# YTM32B1MD2 register map
Vendor: YTMicro; File version: 1.0
CPU: CM33 r0p4, little endian, MPU, FPU, 2 interrupt priority bits
Registers are 32-bit, read-write, reset 0x0 unless marked. A register's access mark holds for its fields unless they carry their own. Offsets are from the block's base; [hi:lo] are bit positions; {n}, {i} and the like mark numbered series.

## TRNG0 — True Random Number Generator
Base 0x40066000; register names take the prefix TRNG0_
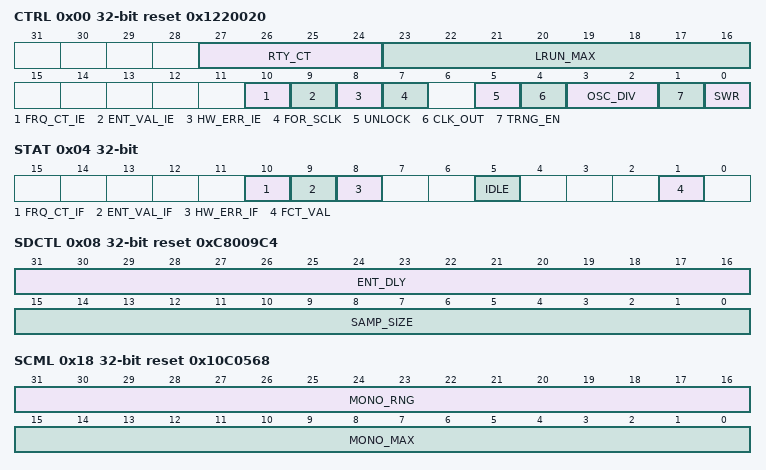
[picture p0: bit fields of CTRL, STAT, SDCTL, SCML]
0x00 CTRL reset 0x1220020
  [27:24] RTY_CT — It indicates the number of times a retry should occur before generating an error. Retry occurs when the statistical check fails during the TRNG entropy generation. This bit is writable only if UNLOCK bit is 1, or the UNLOCK bit is being written to 1 simultaneously.
  [23:16] LRUN_MAX — It is the largest allowable number of consecutive samples of all 1 or all 0 during the entropy generation. This bit is writable only if UNLOCK bit is 1, or the UNLOCK bit is being written to 1 simultaneously.
  [10] FRQ_CT_IE
    0=Interrupt disable; 1=Interrupt enable
  [9] ENT_VAL_IE
    0=Interrupt disable; 1=Interrupt enable
  [8] HW_ERR_IE
    0=Interrupt disable; 1=Interrupt enable
  [7] FOR_SCLK — If the bit is set, the system clock is used to operate the TRNG instead of the ring OSC. This bit is writable only if UNLOCK bit is 1, or the UNLOCK bit is being written to 1 simultaneously.
    0=No effect; 1=Force the system clock to operate the TRNG instead of the ring OSC
  [5] UNLOCK — This bit can prevent the value of various control bits from changing due to unexpected operation.
    0=Lock. Write to the control bits has no effect. Write 0 to start entropy generation.; 1=Unlock. The control bits are able to be modified. Write 1 to stop entropy generation.
  [4] CLK_OUT — After divided by 10, trng_osc_clk is output for test.
    0=No effect; 1=trng_osc_clk is output for test
  [3:2] OSC_DIV — This field is writable only if UNLOCK bit is 1, or the UNLOCK bit is being written to 1 simultaneously.
    0=No devider; 1=Ring OSC divided by 2; 2=Ring OSC divided by 4; 3=Ring OSC divided by 8
  [1] TRNG_EN — Enable the TRNG to generate and entropy value that can be read via ENT registers.
    0=TRNG disable; 1=TRNG enable
  [0] SWR wo — Writing 1 to this bit clears various TRNG registers(RTY_CT, LRUN_MAX, FOR_SCLK, CLK_OUT, OSC_DIV, SAMP_SIZE and SCML) to their default state. This bit is writable only if UNLOCK bit is 1, or the UNLOCK bit is being written to 1 simultaneously.
    0=No effect; 1=Software reset
0x04 STAT
  [10] FRQ_CT_IF ro — It indicate the frequency counter has detected a failure. The FRQMAX and FRQMIN registers has effect on it.
    0=Frequency count success; 1=Frequency count fail
  [9] ENT_VAL_IF ro — When entropy generation succeed, the TRNG will generate an entropy value that can be read via ENT registers and assert this bit.
    0=No valid entropy value; 1=Valid entropy value can be read
  [8] HW_ERR_IF ro
    0=No hardware error; 1=Hardware error happens
  [5] IDLE ro — The status of the entropy generation FSM.
    0=State idle; 1=State busy
  [1] FCT_VAL ro — The frequency count for trng_osc_clk is valid to read.
    0=The frequency count for trng_osc_clk is not ready for read; 1=The frequency count for trng_osc_clk is ready to read
0x08 SDCTL reset 0xC8009C4
  [31:16] ENT_DLY — Defines the length of each entropy sample taken. This bit is writable only if UNLOCK bit is 1.
  [15:0] SAMP_SIZE — Defines the total number of entropy samples taken during entropy generation. This bit is writable only if UNLOCK bit is 1.
0x0C FRQMIN reset 0x640
  [21:0] FRQ_MIN — Define the minimum allowable count taken during each entropy sample. This bit is writable only if UNLOCK bit is 1.
0x10 FRQMAX reset 0x6400
  [21:0] FRQ_MAX — Define the maximum allowable count taken during each entropy sample. This bit is writable only if UNLOCK bit is 1.
0x14 FRQCNT
  [21:0] FRQ_CT ro — When STAT[ENT_VAL_IF]=1, reads a sample frequency count takes during entropy generation.
0x18 SCML reset 0x10C0568
  [31:16] MONO_RNG wo — The number of ones detected during entropy generation must be greater than MONO_MAX - MONO_RNG, otherwise a retry or error will occur. This field is writable only if UNLOCK bit is 1.
  [15:0] MONO_MAX wo — The number of ones detected during entropy generation must be less than MONO_MAX, otherwise a retry or error will occur. This field is writable only if UNLOCK bit is 1.
0x1C SCMC
  [15:0] MONO_CT ro — Reads the final monobit count after entropy generation. Start from SCML[MONO_MAX], and is decremented each time a "1" is sampled.
{0x40+4i} ENT{i} (i=0..3)
  [31:0] ENT ro — The entropy value will be valid when STAT[ENT_VAL_IF] = 1. Reading the highest offset entropy will clear the entire entropy value and valid flag, and a new entropy generation will start.
